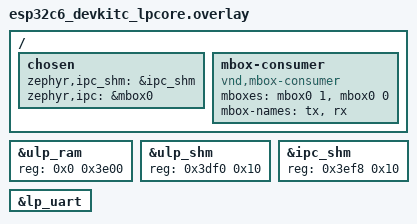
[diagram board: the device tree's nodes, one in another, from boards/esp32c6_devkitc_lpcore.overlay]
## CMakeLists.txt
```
# SPDX-License-Identifier: Apache-2.0

cmake_minimum_required(VERSION 3.20.0)
find_package(Zephyr REQUIRED HINTS $ENV{ZEPHYR_BASE})
project(zephyr_bist_remote)

target_sources(app PRIVATE src/main.c)
```

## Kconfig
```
# Copyright (c) 2025 Espressif Systems (Shanghai) Co., Ltd.
# SPDX-License-Identifier: Apache-2.0

source "Kconfig.zephyr"
```

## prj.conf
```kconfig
CONFIG_MBOX=y
CONFIG_SERIAL=y
CONFIG_PRINTK=y
CONFIG_MAIN_STACK_SIZE=1024
CONFIG_ISR_STACK_SIZE=512
CONFIG_IDLE_STACK_SIZE=32
CONFIG_OUTPUT_DISASSEMBLY=y
# BIST tests to run on the LP core
CONFIG_ESP_BIST=y
CONFIG_ESP_BIST_CPU_REG_TEST=y
CONFIG_ESP_BIST_STACK_TEST=y
CONFIG_ESP_BIST_MEMORY_RAM_TEST=y
# 64-word partitions → 512 B Abraham pair + 512 B backup; fits LP SRAM with HDA.
CONFIG_ESP_BIST_RAM_PARTITION_SIZE=64
CONFIG_ESP_BIST_MEMORY_FLASH_TEST=y
# Host Diagnostics companion (LP side)
CONFIG_ESP_BIST_HOST_DIAGNOSTICS=y
CONFIG_ESP_BIST_HD_AUDIT_QA=y
CONFIG_ESP_BIST_HD_AUDIT_CHECKPOINT=y
CONFIG_ESP_BIST_HD_CHECKPOINT_PERIOD_LOOPS=3
CONFIG_ESP_BIST_HD_AUDIT_IRQ_LATENCY=y
CONFIG_ESP_BIST_HD_IRQ_LATENCY_BUDGET_US=5000
CONFIG_ESP_BIST_HD_AUDIT=y
CONFIG_ESP_BIST_HD_AUDIT_CPU=y
CONFIG_ESP_BIST_HD_AUDIT_CSR=y
CONFIG_ESP_BIST_HD_AUDIT_RAM=y
CONFIG_ESP_BIST_HD_AGENT_READY_TIMEOUT_US=5000000
# Runtime round must stay well inside the 50 ms LP WDT window.
CONFIG_ESP_BIST_RUNTIME_TEST_INTERVAL_MS=10
```

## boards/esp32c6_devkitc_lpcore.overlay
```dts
/*
 * Copyright (c) 2025 Espressif Systems (Shanghai) Co., Ltd.
 *
 * SPDX-License-Identifier: Apache-2.0
 */

/ {
	chosen {
		zephyr,ipc_shm = &ipc_shm;
		zephyr,ipc = &mbox0;
	};

	mbox-consumer {
		compatible = "vnd,mbox-consumer";
		mboxes = <&mbox0 1>, <&mbox0 0>;
		mbox-names = "tx", "rx";
	};
};

&ulp_ram {
	reg = <0x0 0x3e00>;
};

&ulp_shm {
	reg = <0x3df0 0x10>;
};

&ipc_shm {
	reg = <0x3ef8 0x10>;
};

&lp_uart {
	status = "okay";
};
```

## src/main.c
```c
/*
 * Copyright (c) 2026 Espressif Systems (Shanghai) Co., Ltd.
 *
 * SPDX-License-Identifier: Apache-2.0
 */

/*
 * LP-core entry for the ESP-BIST Zephyr sample.
 *
 * Host Diagnostics companion handles LP BIST and status reporting; this
 * main owns the loop so product code can run alongside it. Mirrors
 * samples/idf/main/ulp/main.c so both platforms exercise the same
 * companion behaviour.
 *
 * The LP image has no system clock, so pacing uses the companion port
 * delay rather than k_msleep().
 */

#include <zephyr/kernel.h>

#include <bist_hd_comp_port.h>
#include <bist_hd_companion.h>

#define RUNTIME_INTERVAL_US (CONFIG_ESP_BIST_RUNTIME_TEST_INTERVAL_MS * 1000)

int main(void)
{
	if (bist_hd_companion_init() != 0) {
		return 0;
	}

	while (1) {
		bist_hd_companion_loop();
		/* Application-specific LP logic can go here. */
		bist_hd_comp_port_delay_us(RUNTIME_INTERVAL_US);
	}

	return 0;
}
```
